# DA14681 register map
Vendor: Dialog; Series: DA14681; File version: 1.2
CPU: CM0 r1p0, little endian, MPU, FPU, 3 interrupt priority bits
Registers are 16-bit, read-write, reset 0x0 unless marked. A register's access mark holds for its fields unless they carry their own. Offsets are from the block's base; [hi:lo] are bit positions; {n}, {i} and the like mark numbered series; 'fields as' and 'values as' point back to an identical list.

## COEX — COEX registers
Base 0x50002F00
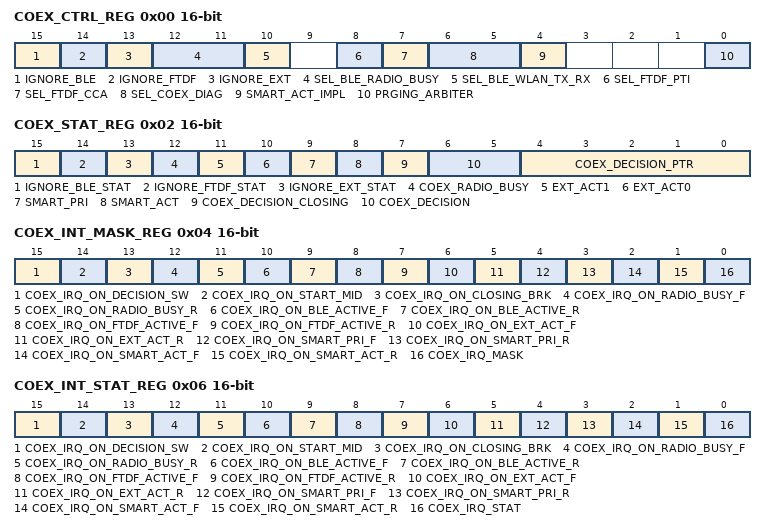
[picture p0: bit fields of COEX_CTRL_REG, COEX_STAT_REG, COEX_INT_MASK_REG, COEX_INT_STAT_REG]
0x00 COEX_CTRL_REG — COEX Control Register
  [15] IGNORE_BLE — If set to "1" then all BLE requests are ignored by masking the internal "ble_active" signal. Refer also to IGNORE_BLE_STAT.
  [14] IGNORE_FTDF — If set to "1" then all FTDF requests are ignored by masking the internal "ftdf_active" signal. Refer also to IGNORE_FTDF_STAT.
  [13] IGNORE_EXT — If set to "1" then all EXT requests are ignored by masking the internal "ext_act" signal ("ext_act" is the logical OR of "ext_act0" and "ext_act1"). Refer also to IGNORE_EXT_STAT.
  [12:11] SEL_BLE_RADIO_BUSY — Select the logic driving the BLE core input "ble.radio_busy": 0: (decision==BLE) AND rfcu.radio_busy. 1: Hold to "0". 2: (decision==FTDF) OR (decision==EXT) OR rfcu.radio_busy. 3: (decision==FTDF) OR (decision==EXT). Selection "0" is the default, while selection "2" is the recommended value if the BLE SW supports it.
  [10] SEL_BLE_WLAN_TX_RX — If set to "1" then the COEX block will drive the WLAN_TX and WLAN_RX inputs of the BLE core. Otherwise both BLE inputs will be forced to "0".
  [8] SEL_FTDF_PTI — It controls the source of the FTDF PTI value that the COEX Arbiter will use. If "0" then use the COEX_FTDF_PTI_REG. If "1" then use the PTI value provided by the FTDF core.
  [7] SEL_FTDF_CCA — If set to "1" and the COEX decision is different than "FTDF", then the CCA_STAT signal going to FTDF (generated from the radio) will be forced to "1"; otherwise the FTDF.CCA_STAT will be driven with the signal generated from the radio. Recommended value for SEL_FTDF_CCA is "1".
  [6:5] SEL_COEX_DIAG — The COEX block can provide internal diagnostic signals by overwriting the BLE diagnostic bus, which is forwarded to GPIO multiplexing. There is no need to program the BLE registers, but only this field and the GPIO PID fields. The encoding of this bitfield is: 0: Don't overwrite any BLE diagnostic signal. 1: Overwrite the BLE Diagnostic bits 2 down to 0: P2[2]: "closing" sub-state P2[1:0]:"decision" state 2: Overwrite the BLE Diagnostic bits 5 down to 3: P1[2]: "closing" sub-state P1[1:0]:"decision" state 3: Reserved..
  [4] SMART_ACT_IMPL — Controls the behavior of the SMART_ACT (and SMART_PRI as a consequence). If SMART_ACT_IMPL="0" then if any BLE or FTDF MAC request is active then SMART_ACT will be asserted. SMART_ACT will actually be the logical OR of "ble_active" and "ftdf_active" internal signals. SMART_ACT will be asserted regardless the decision of the Arbiter to allow or disallow the access to the on-chip radio from the active MAC(s). if SMART_ACT_IMPL="1" then if the Arbiter's decision is to allow EXTernal MAC, then keep SMART_ACT to "0", otherwise follow the implementation of SMART_ACT_IMPL="0".
  [0] PRGING_ARBITER — If set to "1" then the current BLE transaction will complete normally and after that no further decision will be taken by the arbiter. The SW must keep this bit to "1" as long as it performs write operations on the COEX_PRI*_REG registers. As soon as the update on the priority registers will be completed, the SW should clear this bit. Note: This bit is updated with the COEX_CLK, so depending on the relationship between the PCLK and COEX_CLK periods a write operation to this bit may be effective in more than one PCLK clock cycles, e.g. when the COEX_CLK rate is slower than the PCLK.
0x02 COEX_STAT_REG — COEX Status Register
  [15] IGNORE_BLE_STAT ro — This signal is constantly "1" on FTDF-only chips. If set to "1" then all BLE requests are ignored by masking immediately the request signal from the BLE. In more detail, the internal signal "ble_active" is the logical AND of this bitfield and the "ble.event_in_process".
  [14] IGNORE_FTDF_STAT ro — This signal is constantly "1" on BLE-only chips. If set to "1" then all FTDF requests are ignored by masking immediately the request signal from the FTDF. In more detail, the internal signal "ftdf_active" is the logical AND of this bitfield and the "ftdf.phy_en".
  [13] IGNORE_EXT_STAT ro — If set to "1" then all EXT requests are ignored by masking immediately the request signal from the external MAC. In more detail, the internal signal "ext_active" is the logical AND of this bitfield and the "ext_act".
  [12] COEX_RADIO_BUSY ro — Current state of RADIO_BUSY signal generated from RFCU, which is the logical OR among all Radio DCFs. Note that the arbiter will process this value with one COEX clock cycle delay.
  [11] EXT_ACT1 ro — Current state of the pin.
  [10] EXT_ACT0 ro — Current state of the pin.
  [9] SMART_PRI ro — Current state of the pin.
  [8] SMART_ACT ro — Current state of the pin.
  [7] COEX_DECISION_CLOSING ro — Provides the value of the "CLOSING" substate.
  [6:5] COEX_DECISION ro — Decision values: 0: Decision is NONE. 1: Decision is BLE. 2: Decision is FTDF. 3: Decision is EXT. Note: If "0" (i.e. decision is NONE) then no MAC will have access to the on-chip radio. As a consequence, the SMART_PRI signal will stay low, since no on-chip (SMART) MAC will have priority. Note: The decision NONE will be held as long as there is no "*_active" internal signal from BLE, FTDF or EXT. Also, if in programming state and the last transaction has been finished, then the decision will be held also to NONE. Note: While in programming mode, the COEX_PRIx_REGs are considered as invalid, which means that no new decision can be taken.
  [4:0] COEX_DECISION_PTR ro — Provides the number "x" of the COEX_PRIx_REG that win the last arbitration cycle. If "0" then it is a null pointer, pointing to no COEX_PRIx_REG.
0x04 COEX_INT_MASK_REG — COEX Interrupt Mask Register
  [15] COEX_IRQ_ON_DECISION_SW — If "1" then a "1" on COEX_INT_STAT_REG[COEX_IRQ_ON_DECISION_SW] will cause COEX_IRQ_STAT to be set also to "1".
  [14] COEX_IRQ_ON_START_MID — If "1" then a "1" on COEX_INT_STAT_REG[COEX_IRQ_ON_START_MID] will cause COEX_IRQ_STAT to be set also to "1".
  [13] COEX_IRQ_ON_CLOSING_BRK — If "1" then a "1" on COEX_INT_STAT_REG[COEX_IRQ_ON_CLOSING_BRK] will cause COEX_IRQ_STAT to be set also to "1".
  [12] COEX_IRQ_ON_RADIO_BUSY_F — If "1" then a "1" on COEX_INT_STAT_REG[COEX_IRQ_ON_RADIO_BUSY_F] will cause COEX_IRQ_STAT to be set also to "1".
  [11] COEX_IRQ_ON_RADIO_BUSY_R — If "1" then a "1" on COEX_INT_STAT_REG[COEX_IRQ_ON_RADIO_BUSY_R] will cause COEX_IRQ_STAT to be set also to "1".
  [10] COEX_IRQ_ON_BLE_ACTIVE_F — If "1" then a "1" on COEX_INT_STAT_REG[COEX_IRQ_ON_BLE_ACTIVE_F] will cause COEX_IRQ_STAT to be set also to "1".
  [9] COEX_IRQ_ON_BLE_ACTIVE_R — If "1" then a "1" on COEX_INT_STAT_REG[COEX_IRQ_ON_BLE_ACTIVE_R] will cause COEX_IRQ_STAT to be set also to "1".
  [8] COEX_IRQ_ON_FTDF_ACTIVE_F — If "1" then a "1" on COEX_INT_STAT_REG[COEX_IRQ_ON_FTDF_ACTIVE_F] will cause COEX_IRQ_STAT to be set also to "1".
  [7] COEX_IRQ_ON_FTDF_ACTIVE_R — If "1" then a "1" on COEX_INT_STAT_REG[COEX_IRQ_ON_FTDF_ACTIVE_R] will cause COEX_IRQ_STAT to be set also to "1".
  [6] COEX_IRQ_ON_EXT_ACT_F — If "1" then a "1" on COEX_INT_STAT_REG[COEX_IRQ_ON_EXT_ACT_F] will cause COEX_IRQ_STAT to be set also to "1".
  [5] COEX_IRQ_ON_EXT_ACT_R — If "1" then a "1" on COEX_INT_STAT_REG[COEX_IRQ_ON_EXT_ACT_R] will cause COEX_IRQ_STAT to be set also to "1".
  [4] COEX_IRQ_ON_SMART_PRI_F — If "1" then a "1" on COEX_INT_STAT_REG[COEX_IRQ_ON_SMART_PRI_F] will cause COEX_IRQ_STAT to be set also to "1".
  [3] COEX_IRQ_ON_SMART_PRI_R — If "1" then a "1" on COEX_INT_STAT_REG[COEX_IRQ_ON_SMART_PRI_R] will cause COEX_IRQ_STAT to be set also to "1".
  [2] COEX_IRQ_ON_SMART_ACT_F — If "1" then a "1" on COEX_INT_STAT_REG[COEX_IRQ_ON_SMART_ACT_F] will cause COEX_IRQ_STAT to be set also to "1".
  [1] COEX_IRQ_ON_SMART_ACT_R — If "1" then a "1" on COEX_INT_STAT_REG[COEX_IRQ_ON_SMART_ACT_R] will cause COEX_IRQ_STAT to be set also to "1".
  [0] COEX_IRQ_MASK — If set to "1" then sent an COEX_IRQ event to CPU as long as COEX_INT_STAT_REG[COEX_IRQ_STAT] is "1". If cleared then don't sent any IRQ event to CPU.
0x06 COEX_INT_STAT_REG — COEX Interrupt Status Register
  [15] COEX_IRQ_ON_DECISION_SW ro — IRQ event when the decision switches to a new MAC. It ignores the intermediate transitions to DECISION==NONE. Note that after a Radio domain reset, the first transition of the decision to any MAC will also trigger this event.
  [14] COEX_IRQ_ON_START_MID ro — IRQ event when the decision switches to a MAC, while the TX_EN or RX_EN of this MAC are high. This event signals a potential break of a transmission or reception.
  [13] COEX_IRQ_ON_CLOSING_BRK ro — IRQ if while entering into "closing" sub-state, the TX_EN or RX_EN are active. This event signals a potential break of a transmission or reception.
  [12] COEX_IRQ_ON_RADIO_BUSY_F ro — IRQ event on falling edge of RADIO_BUSY.
  [11] COEX_IRQ_ON_RADIO_BUSY_R ro — IRQ event on rising edge of RADIO_BUSY.
  [10] COEX_IRQ_ON_BLE_ACTIVE_F ro — IRQ event on falling edge of BLE_ACTIVE internal signal.
  [9] COEX_IRQ_ON_BLE_ACTIVE_R ro — IRQ event on rising edge of BLE_ACTIVE internal signal.
  [8] COEX_IRQ_ON_FTDF_ACTIVE_F ro — IRQ event on falling edge of FTDF_ACTIVE internal signal.
  [7] COEX_IRQ_ON_FTDF_ACTIVE_R ro — IRQ event on rising edge of FTDF_ACTIVE internal signal.
  [6] COEX_IRQ_ON_EXT_ACT_F ro — RQ event on falling edge of EXT_ACT.
  [5] COEX_IRQ_ON_EXT_ACT_R ro — IRQ event on rising edge of EXT_ACT.
  [4] COEX_IRQ_ON_SMART_PRI_F ro — IRQ event on falling edge of SMART_PRI.
  [3] COEX_IRQ_ON_SMART_PRI_R ro — IRQ event on rising edge of SMART_PRI.
  [2] COEX_IRQ_ON_SMART_ACT_F ro — IRQ event on falling edge of SMART_ACT.
  [1] COEX_IRQ_ON_SMART_ACT_R ro — IRQ event on rising edge of SMART_ACT.
  [0] COEX_IRQ_STAT ro — For each COEX_IRQ_ON_* bitfield of COEX_INT_STAT_REG the corresponding mask is applied and afterwards all the intermediate results are combined with a logical OR in order to produce the COEX_IRQ_STAT bitfield. If furthermore the COEX_INT_MASK_REG[COEX_IRQ_MASK] is set to "1", then a COEX_IRQ signal will be forwarded to the CPU. Note: Each COEX_IRQ_ON_* bitfield of COEX_INT_STAT_REG will be set to "1" on the detection of the corresponding event and will be cleared to "0" on the read of COEX_INT_STAT_REG. The automated clear may delay a couple of PCLK cycles, depending on the relationship between PCLK and COEX_CLK.
0x08 COEX_BLE_PTI_REG — COEX BLE PTI Control Register
  [2:0] COEX_BLE_PTI — This value specifies the PTI value that characterizes the next BLE transaction that will be initiated on the following "ble_active" positive edge. The value should remain constant during the high period of the "ble_active" signal.
0x0A COEX_FTDF_PTI_REG — COEX FTDF PTI Control Register
  [2:0] COEX_FTDF_PTI — This value specifies the PTI value that characterizes the next FTDF transaction that will be initiated on the following "ftdf_active" positive edge. The value should remain constant during the high period of the "ftdf_active" signal. Refer also to bitfield COEX_CTRL_REG.SEL_FTDF_PTI.
0x0C COEX_DIAG_REG — COEX Diagnostic Monitor Register
  [15:0] COEX_DIAG_MON ro — provides the current value of the diagnostic bus forwarded to the GPIO multiplexing (named PPA). Refer to the Pxy_MODE_REG[PID] value BLE_DIAG.
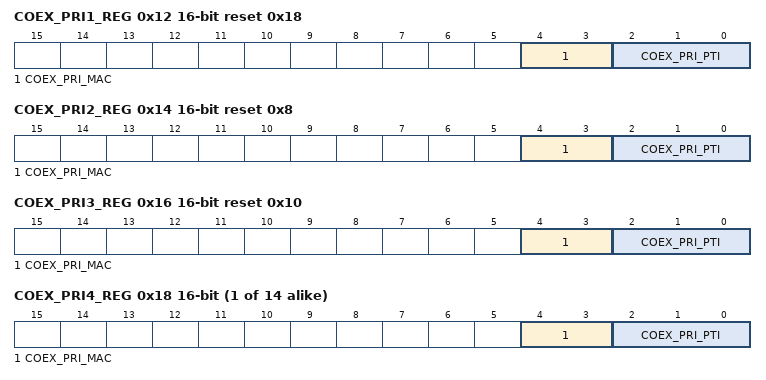
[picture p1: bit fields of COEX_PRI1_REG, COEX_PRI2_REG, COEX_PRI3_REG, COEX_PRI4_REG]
0x12 COEX_PRI1_REG reset 0x18 — COEX Priority Register
  [4:3] COEX_PRI_MAC — Specifies the MAC that has been assigned with the specific priority level. The MAC encoding follows the COEX_DECISION bitfield encoding.
  [2:0] COEX_PRI_PTI — The priority level specified by this register will be applied to the packets coming from the MAC specified by the COEX_PRI_MAC bitfield and characterized with the PTI value specified by the COEX_PRI_PTI bitfield.
0x14 COEX_PRI2_REG reset 0x8 — COEX Priority Register
  [4:3] COEX_PRI_MAC — Refer to COEX_PRI1_REG.
  [2:0] COEX_PRI_PTI — Refer to COEX_PRI1_REG.
0x16 COEX_PRI3_REG reset 0x10 — COEX Priority Register
  fields as COEX_PRI2_REG
{0x10+2i} COEX_PRI{i}_REG (i=4..17) — COEX Priority Register
  fields as COEX_PRI2_REG
